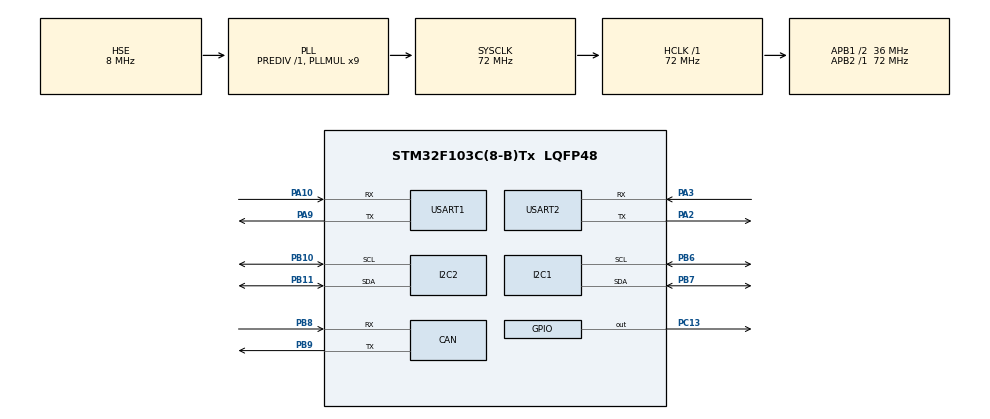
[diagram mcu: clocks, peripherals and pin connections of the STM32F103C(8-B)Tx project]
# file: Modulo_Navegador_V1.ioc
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CAN.CalculateTimeBit=1333
CAN.CalculateTimeQuantum=444.44444444444446
Mcu.Family=STM32F1
Mcu.Name=STM32F103C(8-B)Tx
Mcu.Package=LQFP48
NVIC.PriorityGroup=NVIC_PRIORITYGROUP_4
NVIC.TIM2_IRQn=true\:0\:0\:false\:false\:true\:true\:true
NVIC.USB_LP_CAN1_RX0_IRQn=true\:0\:0\:false\:false\:true\:true\:true
PA10.Mode=Asynchronous
PA10.Signal=USART1_RX
PA2.Mode=Asynchronous
PA2.Signal=USART2_TX
PA3.Mode=Asynchronous
PA3.Signal=USART2_RX
PA9.Mode=Asynchronous
PA9.Signal=USART1_TX
PB10.Mode=I2C
PB10.Signal=I2C2_SCL
PB11.Mode=I2C
PB11.Signal=I2C2_SDA
PB6.Mode=I2C
PB6.Signal=I2C1_SCL
PB7.Mode=I2C
PB7.Signal=I2C1_SDA
PB8.Mode=Master
PB8.Signal=CAN_RX
PB9.Mode=Master
PB9.Signal=CAN_TX
PC13-TAMPER-RTC.Signal=GPIO_Output
PD0-OSC_IN.Mode=HSE-External-Oscillator
PD0-OSC_IN.Signal=RCC_OSC_IN
PD1-OSC_OUT.Mode=HSE-External-Oscillator
PD1-OSC_OUT.Signal=RCC_OSC_OUT
ProjectManager.HeapSize=0x200
ProjectManager.StackSize=0x400
ProjectManager.TargetToolchain=TrueSTUDIO
RCC.ADCPresc=RCC_ADCPCLK2_DIV6
RCC.AHBFreq_Value=72000000
RCC.APB1CLKDivider=RCC_HCLK_DIV2
RCC.APB1Freq_Value=36000000
RCC.APB1TimFreq_Value=72000000
RCC.APB2Freq_Value=72000000
RCC.APB2TimFreq_Value=72000000
RCC.HCLKFreq_Value=72000000
RCC.PLLMUL=RCC_PLL_MUL9
RCC.PLLSourceVirtual=RCC_PLLSOURCE_HSE
RCC.SYSCLKFreq_VALUE=72000000
RCC.SYSCLKSource=RCC_SYSCLKSOURCE_PLLCLK
RCC.USBFreq_Value=72000000
TIM2.Period=999
TIM2.Prescaler=7999
USART1.VirtualMode=VM_ASYNC
USART2.VirtualMode=VM_ASYNC
VP_SYS_VS_ND.Mode=No_Debug
VP_TIM2_VS_ClockSourceINT.Mode=Internal
board=custom

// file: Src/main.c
/*

	 .d88888b.  8888888b.  8888888888 888b     d888 888     888  .d8888b.
	d88P" "Y88b 888   Y88b 888        8888b   d8888 888     888 d88P  Y88b
	888     888 888    888 888        88888b.d88888 888     888 Y88b.
	888     888 888   d88P 8888888    888Y88888P888 888     888  "Y888b.
	888     888 8888888P"  888        888 Y888P 888 888     888     "Y88b.
	888     888 888 T88b   888        888  Y8P  888 888     888       "888
	Y88b. .d88P 888  T88b  888        888   "   888 Y88b. .d88P Y88b  d88P
	 "Y88888P"  888   T88b 8888888888 888       888  "Y88888P"   "Y8888P"

  ******************************************************************************
  *    M  O  D  U  L  O     N  A  V  E  G  A  D  O  R  -  Versão 4   5/04/2020
  ******************************************************************************

	USART1_TX  -> PA9
	USART1_RX  -> PA10

	USART2_TX  -> PA2
	USART2_RX  -> PA3

	CAN_TX -> PB9
	CAN_RX -> PB8

	I2C1_SDA -> PB7
	I2C1_SCL -> PB6

	I2C2_SDA -> PB11
	I2C2_SCL -> PB10

    PA5  -> LED

    PB1  -> Profundimetro

 */

/* USER CODE BEGIN Header */
/**
  ******************************************************************************
  * @file           : main.c
  * @brief          : Main program body
  ******************************************************************************
  * @attention
  *
  * <h2><center>&copy; Copyright (c) 2020 STMicroelectronics.
  * All rights reserved.</center></h2>
  *
  * This software component is licensed by ST under BSD 3-Clause license,
  * the "License"; You may not use this file except in compliance with the
  * License. You may obtain a copy of the License at:
  *                        opensource.org/licenses/BSD-3-Clause
  *
  ******************************************************************************
  */
/* USER CODE END Header */

#include "main.h"

CAN_HandleTypeDef hcan;

I2C_HandleTypeDef hi2c1;
I2C_HandleTypeDef hi2c2;

TIM_HandleTypeDef htim2;

UART_HandleTypeDef huart1;
UART_HandleTypeDef huart2;

static CAN_TxHeaderTypeDef TxHeader;
static CAN_RxHeaderTypeDef RxHeader;
uint8_t TxData[8];
uint8_t RxData[8];
uint32_t TxMailbox;

union U{
		uint32_t var32;
		uint8_t var8[4];
	}u;

void SystemClock_Config(void);
static void MX_GPIO_Init(void);
static void MX_TIM2_Init(void);
static void MX_CAN_Init(void);
static void MX_I2C1_Init(void);
static void MX_I2C2_Init(void);
static void MX_USART1_UART_Init(void);
static void MX_USART2_UART_Init(void);

int main(void)
{

  /* MCU Configuration--------------------------------------------------------*/

  /* Reset of all peripherals, Initializes the Flash interface and the Systick. */
  HAL_Init();

  /* Configure the system clock */
  SystemClock_Config();

  /* Initialize all configured peripherals */
  MX_GPIO_Init();
  MX_TIM2_Init();
  MX_CAN_Init();
  MX_I2C1_Init();
  MX_I2C2_Init();
  MX_USART1_UART_Init();
  MX_USART2_UART_Init();

  /* Infinite loop */
  /* USER CODE BEGIN WHILE */
  while (1)
  {

      HAL_GPIO_TogglePin(GPIOA,GPIO_PIN_5);

	  TxHeader.StdId = 0x003; // responde com id 0x00B
	  TxData[0] = TxData[0];
	  TxData[1] = TxData[1];
	  TxData[2] = 112;
	  TxData[3] = TxData[3];
	  TxData[4] = TxData[4];
	  TxData[5] = TxData[5];
	  HAL_Delay(1000);

	  		      if (HAL_CAN_AddTxMessage(&hcan, &TxHeader, TxData, &TxMailbox) != HAL_OK)
      {
        Error_Handler();
      }

	  TxHeader.StdId = 0x003; // responde com id 0x00B
	  TxData[0] = TxData[0];
	  TxData[1] = TxData[1];
	  TxData[2] = 37;
	  TxData[3] = TxData[3];
	  TxData[4] = TxData[4];
	  TxData[5] = TxData[5];
	  HAL_Delay(1000);

	  	  	  	  if (HAL_CAN_AddTxMessage(&hcan, &TxHeader, TxData, &TxMailbox) != HAL_OK)
      {
       Error_Handler();
      }

  }
}

void SystemClock_Config(void)
{
  RCC_OscInitTypeDef RCC_OscInitStruct = {0};
  RCC_ClkInitTypeDef RCC_ClkInitStruct = {0};

  /** Initializes the CPU, AHB and APB busses clocks
  */
  RCC_OscInitStruct.OscillatorType = RCC_OSCILLATORTYPE_HSE;
  RCC_OscInitStruct.HSEState = RCC_HSE_ON;
  RCC_OscInitStruct.HSEPredivValue = RCC_HSE_PREDIV_DIV1;
  RCC_OscInitStruct.HSIState = RCC_HSI_ON;
  RCC_OscInitStruct.PLL.PLLState = RCC_PLL_ON;
  RCC_OscInitStruct.PLL.PLLSource = RCC_PLLSOURCE_HSE;
  RCC_OscInitStruct.PLL.PLLMUL = RCC_PLL_MUL9;
  if (HAL_RCC_OscConfig(&RCC_OscInitStruct) != HAL_OK)
  {
    Error_Handler();
  }
  /** Initializes the CPU, AHB and APB busses clocks
  */
  RCC_ClkInitStruct.ClockType = RCC_CLOCKTYPE_HCLK|RCC_CLOCKTYPE_SYSCLK
                              |RCC_CLOCKTYPE_PCLK1|RCC_CLOCKTYPE_PCLK2;
  RCC_ClkInitStruct.SYSCLKSource = RCC_SYSCLKSOURCE_PLLCLK;
  RCC_ClkInitStruct.AHBCLKDivider = RCC_SYSCLK_DIV1;
  RCC_ClkInitStruct.APB1CLKDivider = RCC_HCLK_DIV2;
  RCC_ClkInitStruct.APB2CLKDivider = RCC_HCLK_DIV1;

  if (HAL_RCC_ClockConfig(&RCC_ClkInitStruct, FLASH_LATENCY_2) != HAL_OK)
  {
    Error_Handler();
  }
}

static void MX_CAN_Init(void)
{

  hcan.Instance = CAN1;
  hcan.Init.Prescaler = 9;
  hcan.Init.Mode = CAN_MODE_NORMAL;
  hcan.Init.SyncJumpWidth = CAN_SJW_1TQ;
  hcan.Init.TimeSeg1 = CAN_BS1_13TQ;
  hcan.Init.TimeSeg2 = CAN_BS2_2TQ;
  hcan.Init.TimeTriggeredMode = DISABLE;
  hcan.Init.AutoBusOff = DISABLE;
  hcan.Init.AutoWakeUp = DISABLE;
  hcan.Init.AutoRetransmission = DISABLE;
  hcan.Init.ReceiveFifoLocked = DISABLE;
  hcan.Init.TransmitFifoPriority = DISABLE;
  if (HAL_CAN_Init(&hcan) != HAL_OK)
  {
    Error_Handler();
  }
  /* USER CODE BEGIN CAN_Init 2 */
  if (HAL_CAN_ActivateNotification(&hcan, CAN_IT_RX_FIFO0_MSG_PENDING) != HAL_OK)
  {
	Error_Handler();
  }

  /* Configure the CAN Filter */
  CAN_FilterTypeDef  sFilterConfig;
  sFilterConfig.FilterBank = 0;
  sFilterConfig.FilterMode = CAN_FILTERMODE_IDMASK;
  sFilterConfig.FilterScale = CAN_FILTERSCALE_32BIT;
  sFilterConfig.FilterIdHigh     = 0x000<<5; //0x000
  sFilterConfig.FilterIdLow      = 0x0000;
  sFilterConfig.FilterMaskIdHigh = 0x700<<5; // mascara que filtra
  sFilterConfig.FilterMaskIdLow  = 0x0000;
  sFilterConfig.FilterFIFOAssignment = CAN_RX_FIFO0;
  sFilterConfig.FilterActivation = ENABLE;
  sFilterConfig.SlaveStartFilterBank = 14;
  if (HAL_CAN_ConfigFilter(&hcan, &sFilterConfig) != HAL_OK)
  {
    /* Filter configuration Error */
    Error_Handler();
  }

  /* Configure Transmission process */
  TxHeader.StdId = 0x001;
  TxHeader.ExtId = 0x001;
  TxHeader.RTR = CAN_RTR_DATA;
  TxHeader.IDE = CAN_ID_STD;
  TxHeader.DLC = 8;
  TxHeader.TransmitGlobalTime = DISABLE;

  /* Start the CAN peripheral */
  if (HAL_CAN_Start(&hcan) != HAL_OK)
  {
    /* Start Error */
    Error_Handler();
  }

  /* USER CODE END CAN_Init 2 */

}

static void MX_I2C1_Init(void)
{

  hi2c1.Instance = I2C1;
  hi2c1.Init.ClockSpeed = 100000;
  hi2c1.Init.DutyCycle = I2C_DUTYCYCLE_2;
  hi2c1.Init.OwnAddress1 = 0;
  hi2c1.Init.AddressingMode = I2C_ADDRESSINGMODE_7BIT;
  hi2c1.Init.DualAddressMode = I2C_DUALADDRESS_DISABLE;
  hi2c1.Init.OwnAddress2 = 0;
  hi2c1.Init.GeneralCallMode = I2C_GENERALCALL_DISABLE;
  hi2c1.Init.NoStretchMode = I2C_NOSTRETCH_DISABLE;
  if (HAL_I2C_Init(&hi2c1) != HAL_OK)
  {
    Error_Handler();
  }

}

static void MX_I2C2_Init(void)
{

  hi2c2.Instance = I2C2;
  hi2c2.Init.ClockSpeed = 100000;
  hi2c2.Init.DutyCycle = I2C_DUTYCYCLE_2;
  hi2c2.Init.OwnAddress1 = 0;
  hi2c2.Init.AddressingMode = I2C_ADDRESSINGMODE_7BIT;
  hi2c2.Init.DualAddressMode = I2C_DUALADDRESS_DISABLE;
  hi2c2.Init.OwnAddress2 = 0;
  hi2c2.Init.GeneralCallMode = I2C_GENERALCALL_DISABLE;
  hi2c2.Init.NoStretchMode = I2C_NOSTRETCH_DISABLE;
  if (HAL_I2C_Init(&hi2c2) != HAL_OK)
  {
    Error_Handler();
  }

}

static void MX_TIM2_Init(void)
{

  TIM_ClockConfigTypeDef sClockSourceConfig = {0};
  TIM_MasterConfigTypeDef sMasterConfig = {0};

  htim2.Instance = TIM2;
  htim2.Init.Prescaler = 7999;
  htim2.Init.CounterMode = TIM_COUNTERMODE_UP;
  htim2.Init.Period = 999;
  htim2.Init.ClockDivision = TIM_CLOCKDIVISION_DIV1;
  htim2.Init.AutoReloadPreload = TIM_AUTORELOAD_PRELOAD_DISABLE;
  if (HAL_TIM_Base_Init(&htim2) != HAL_OK)
  {
    Error_Handler();
  }
  sClockSourceConfig.ClockSource = TIM_CLOCKSOURCE_INTERNAL;
  if (HAL_TIM_ConfigClockSource(&htim2, &sClockSourceConfig) != HAL_OK)
  {
    Error_Handler();
  }
  sMasterConfig.MasterOutputTrigger = TIM_TRGO_RESET;
  sMasterConfig.MasterSlaveMode = TIM_MASTERSLAVEMODE_DISABLE;
  if (HAL_TIMEx_MasterConfigSynchronization(&htim2, &sMasterConfig) != HAL_OK)
  {
    Error_Handler();
  }

}

static void MX_USART1_UART_Init(void)
{

  huart1.Instance = USART1;
  huart1.Init.BaudRate = 115200;
  huart1.Init.WordLength = UART_WORDLENGTH_8B;
  huart1.Init.StopBits = UART_STOPBITS_1;
  huart1.Init.Parity = UART_PARITY_NONE;
  huart1.Init.Mode = UART_MODE_TX_RX;
  huart1.Init.HwFlowCtl = UART_HWCONTROL_NONE;
  huart1.Init.OverSampling = UART_OVERSAMPLING_16;
  if (HAL_UART_Init(&huart1) != HAL_OK)
  {
    Error_Handler();
  }

}

static void MX_USART2_UART_Init(void)
{

  huart2.Instance = USART2;
  huart2.Init.BaudRate = 115200;
  huart2.Init.WordLength = UART_WORDLENGTH_8B;
  huart2.Init.StopBits = UART_STOPBITS_1;
  huart2.Init.Parity = UART_PARITY_NONE;
  huart2.Init.Mode = UART_MODE_TX_RX;
  huart2.Init.HwFlowCtl = UART_HWCONTROL_NONE;
  huart2.Init.OverSampling = UART_OVERSAMPLING_16;
  if (HAL_UART_Init(&huart2) != HAL_OK)
  {
    Error_Handler();
  }

}

static void MX_GPIO_Init(void)
{
  GPIO_InitTypeDef GPIO_InitStruct = {0};

  /* GPIO Ports Clock Enable */
  __HAL_RCC_GPIOC_CLK_ENABLE();
  __HAL_RCC_GPIOD_CLK_ENABLE();
  __HAL_RCC_GPIOA_CLK_ENABLE();
  __HAL_RCC_GPIOB_CLK_ENABLE();

  /*Configure GPIO pin Output Level */
  HAL_GPIO_WritePin(GPIOC, GPIO_PIN_13, GPIO_PIN_RESET);

  /*Configure GPIO pin : PC13 */
  GPIO_InitStruct.Pin = GPIO_PIN_13;
  GPIO_InitStruct.Mode = GPIO_MODE_OUTPUT_PP;
  GPIO_InitStruct.Pull = GPIO_NOPULL;
  GPIO_InitStruct.Speed = GPIO_SPEED_FREQ_LOW;
  HAL_GPIO_Init(GPIOC, &GPIO_InitStruct);

  /*Configure GPIO pin : PA5 */
  GPIO_InitStruct.Pin = GPIO_PIN_5;
  GPIO_InitStruct.Mode = GPIO_MODE_OUTPUT_PP;
  GPIO_InitStruct.Pull = GPIO_NOPULL;
  GPIO_InitStruct.Speed = GPIO_SPEED_FREQ_LOW;
  HAL_GPIO_Init(GPIOA, &GPIO_InitStruct);

}

/* USER CODE BEGIN 4 */
void HAL_CAN_RxFifo0MsgPendingCallback(CAN_HandleTypeDef *hcan)
{
  //HAL_GPIO_TogglePin(GPIOC,GPIO_PIN_13);
  /* Get RX message */
  if (HAL_CAN_GetRxMessage(hcan, CAN_RX_FIFO0, &RxHeader, RxData) != HAL_OK)
  {

    Error_Handler();
  }
}
/* USER CODE END 4 */

void Error_Handler(void)
{
}

/************************ (C) COPYRIGHT STMicroelectronics *****END OF FILE****/
